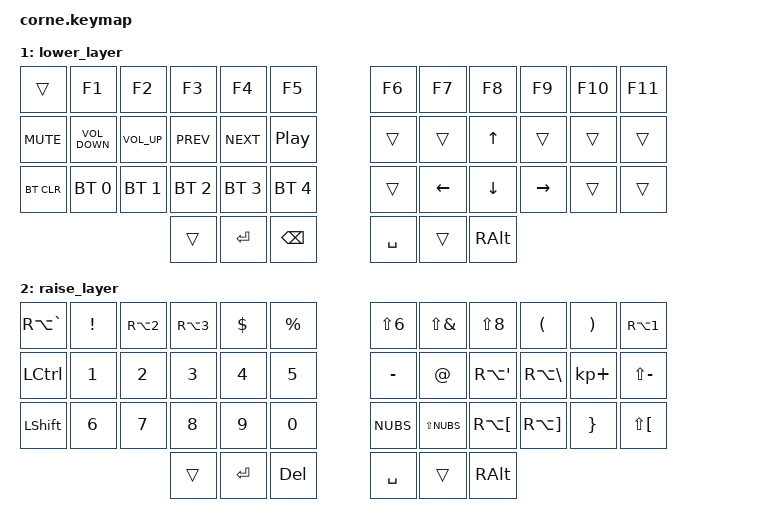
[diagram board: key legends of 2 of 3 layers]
/*
 * Copyright (c) 2020 The ZMK Contributors
 *
 * SPDX-License-Identifier: MIT
 */

#include <behaviors.dtsi>
#include <dt-bindings/zmk/bt.h>
#include <dt-bindings/zmk/keys.h>

/ {
    keymap {
        compatible = "zmk,keymap";

        default_layer {
            // -----------------------------------------------------------------------------------------
            // |  TAB |  Q  |  W  |  E  |  R  |  T  |   |  Y  |  U   |  I  |  O  |  P  | ESC  |
            // | CTRL |  A  |  S  |  D  |  F  |  G  |   |  H  |  J   |  K  |  L  |  ;  |  '   |
            // | SHFT |  Z  |  X  |  C  |  V  |  B  |   |  N  |  M   |  ,  |  .  |  /  | GUI  |
            //                    | ENT | LWR | BKSP|   | SPC | RSE  | ALT |

            bindings = <
&kp TAB    &kp Q  &kp W  &kp E  &kp R      &kp T            &kp Y      &kp U  &kp I         &kp O    &kp P     &kp ESC
&kp LCTRL  &kp A  &kp S  &kp D  &kp F      &kp G            &kp H      &kp J  &kp K         &kp L    &kp SEMI  &kp SINGLE_QUOTE
&kp LSHFT  &kp Z  &kp X  &kp C  &kp V      &kp B            &kp N      &kp M  &kp COMMA     &kp DOT  &kp FSLH  &kp LGUI
                         &mo 1  &kp ENTER  &kp BACKSPACE    &kp SPACE  &mo 2  &kp LEFT_ALT
&kp TAB    &kp Q  &kp W  &kp E         &kp R  &kp T            &kp Y      &kp U      &kp I      &kp O    &kp P     &kp ESC
&kp LCTRL  &kp A  &kp S  &kp D         &kp F  &kp G            &kp H      &kp J      &kp K      &kp L    &kp SEMI  &kp SINGLE_QUOTE
&kp LSHFT  &kp Z  &kp X  &kp C         &kp V  &kp B            &kp N      &kp M      &kp COMMA  &kp DOT  &kp FSLH  &kp LGUI
                         &kp LEFT_ALT  &mo 2  &kp BACKSPACE    &kp SPACE  &kp ENTER  &mo 1
            >;
        };

        lower_layer {
            // -----------------------------------------------------------------------------------------
            // |  TAB |  1  |  2  |  3  |  4  |  5  |   |  6  |  7  |  8  |  9  |  0  | ESC  |
            // | BTCLR| BT1 | BT2 | BT3 | BT4 | BT5 |   | LFT | DWN |  UP | RGT |     |      |
            // | SHFT |     |     |     |     |     |   |     |     |     |     |     |      |
            //                    | ENT |     | BKSP|   | SPC |     | ALT |

            bindings = <
&trans      &kp F1             &kp F2        &kp F3        &kp F4        &kp F5          &kp F6     &kp F7    &kp F8          &kp F9     &kp F10  &kp F11
&kp C_MUTE  &kp C_VOLUME_DOWN  &kp C_VOL_UP  &kp C_PREV    &kp C_NEXT    &kp C_PP        &trans     &trans    &kp UP          &trans     &trans   &trans
&bt BT_CLR  &bt BT_SEL 0       &bt BT_SEL 1  &bt BT_SEL 2  &bt BT_SEL 3  &bt BT_SEL 4    &trans     &kp LEFT  &kp DOWN_ARROW  &kp RIGHT  &trans   &trans
                                             &trans        &kp ENTER     &kp BSPC        &kp SPACE  &trans    &kp RALT
            >;
        };

        raise_layer {
            // -----------------------------------------------------------------------------------------
            // |  TAB |  !  |  @  |  #  |  $  |  %  |   |  ^  |  &  |  *  |  (  |  )  | ESC  |
            // | CTRL |     |     |     |     |     |   |  -  |  =  |  [  |  ]  |  \  |  `   |
            // | SHFT |     |     |     |     |     |   |  _  |  +  |  {  |  }  | "|" |  ~   |
            //                    | ENT |     | BKSP|   | SPC |     | ALT |

            bindings = <
&kp RA(GRAVE)  &kp EXCL  &kp RA(N2)  &kp RA(N3)  &kp DLLR   &kp PRCNT     &kp LS(N6)  &kp LS(AMPERSAND)  &kp LS(N8)            &kp LEFT_PARENTHESIS   &kp RIGHT_PARENTHESIS  &kp RA(N1)
&kp LCTRL      &kp N1    &kp N2      &kp N3      &kp N4     &kp N5        &kp MINUS   &kp AT_SIGN        &kp RA(APOSTROPHE)    &kp RA(BACKSLASH)      &kp KP_PLUS            &kp LS(MINUS)
&kp LSHFT      &kp N6    &kp N7      &kp N8      &kp N9     &kp N0        &kp NUBS    &kp LS(NUBS)       &kp RA(LEFT_BRACKET)  &kp RA(RIGHT_BRACKET)  &kp RIGHT_BRACE        &kp LS(LEFT_BRACKET)
                                     &trans      &kp ENTER  &kp DELETE    &kp SPACE   &trans             &kp RALT
            >;
        };
    };
};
